# DEMO-M4 register map
Demo microcontroller
Registers are 32-bit, read-write, reset 0x0 unless marked. A register's access mark holds for its fields unless they carry their own. Offsets are from the block's base; lines under a group give offsets from that group; [hi:lo] are bit positions; {n}, {i} and the like mark numbered series; 'fields as' and 'values as' point back to an identical list; <NAME> marks a mode.

## Memory map
0x40004400 USART2 — Universal synchronous/asynchronous receiver-transmitter
0x40020000 GPIOA — General-purpose I/O, port A
0x40020400 GPIOB
0x40023800 RCC — Reset and clock control

## RCC — Reset and clock control
Base 0x40023800
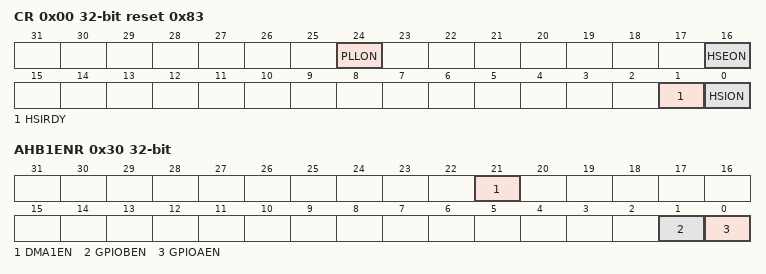
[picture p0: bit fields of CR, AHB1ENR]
0x00 CR reset 0x83 — Clock control
  [24] PLLON
  [16] HSEON — External oscillator on
  [1] HSIRDY ro — Internal oscillator ready
  [0] HSION — Internal oscillator on
0x30 AHB1ENR — AHB1 clock enable
  [21] DMA1EN — Clock for DMA 1
  [1] GPIOBEN — Clock for port B
  [0] GPIOAEN — Clock for port A

## GPIOA — General-purpose I/O, port A
Base 0x40020000
Same registers: GPIOB 0x40020400
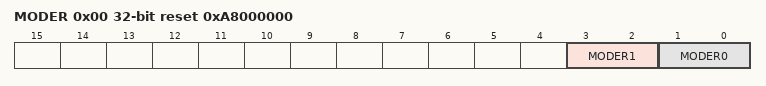
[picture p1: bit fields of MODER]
0x00 MODER reset 0xA8000000 — Port mode
  [3:2] MODER1 — Mode of pin 1
  [1:0] MODER0 — Mode of pin 0
    0=Input; 1=Output; 2=Alternate; 3=Analog
0x10 IDR ro — Input data
  [15:0] IDR — Pin levels
0x14 ODR — Output data
  [15:0] ODR — Output levels

## USART2 — Universal synchronous/asynchronous receiver-transmitter
Base 0x40004400
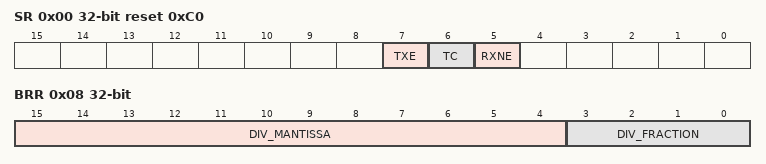
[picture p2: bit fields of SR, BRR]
0x00 SR reset 0xC0 — Status
  [7] TXE ro — Transmit buffer empty
  [6] TC — Transmission complete
  [5] RXNE — Byte received
0x04 DR — Data
  [8:0] DR — Data byte
0x08 BRR — Baud rate
  [15:4] DIV_MANTISSA — Integer part of the divider
  [3:0] DIV_FRACTION — Fraction of the divider
